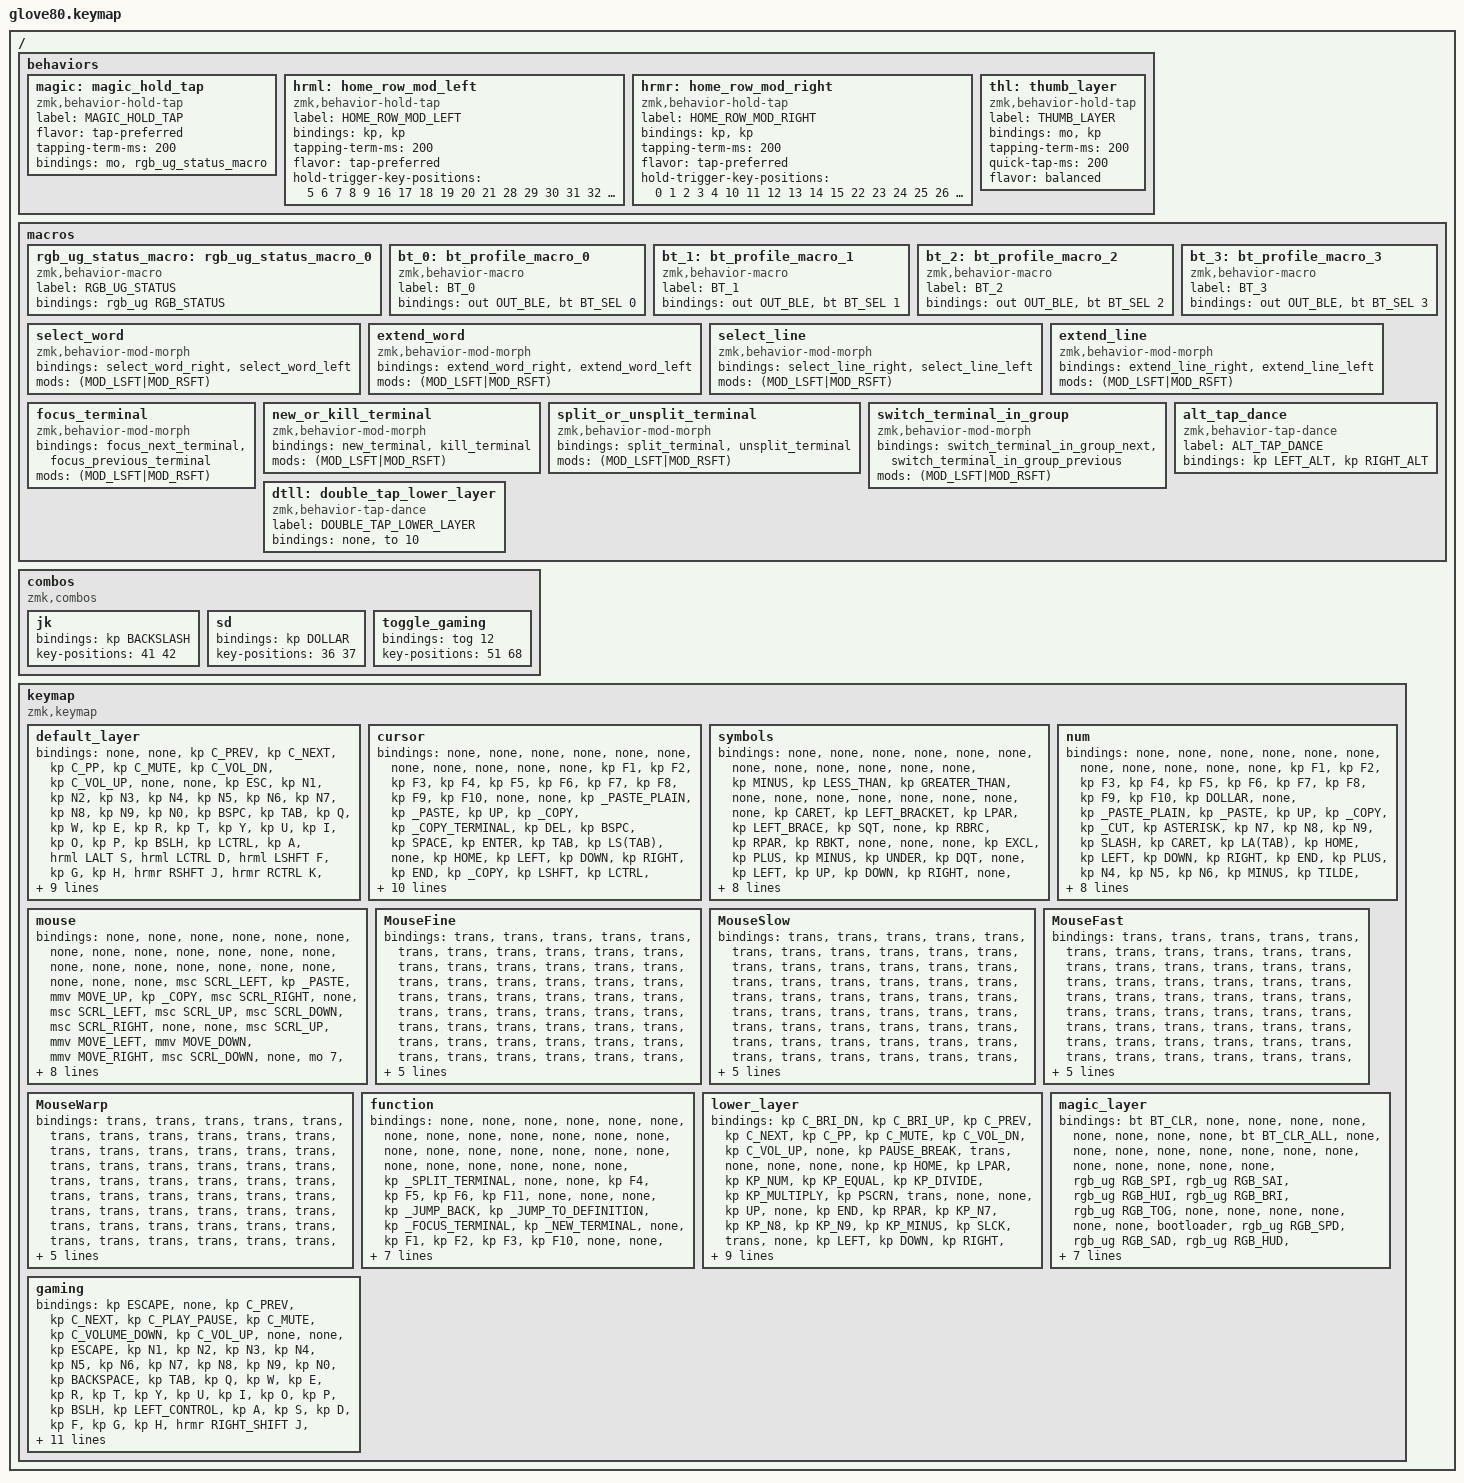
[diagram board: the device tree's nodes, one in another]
#include <input/processors.dtsi>
#include <zephyr/dt-bindings/input/input-event-codes.h>
#include <behaviors.dtsi>
#include <dt-bindings/zmk/bt.h>
#include <dt-bindings/zmk/keys.h>
#include <dt-bindings/zmk/outputs.h>
#include <dt-bindings/zmk/pointing.h>
#include <dt-bindings/zmk/rgb.h>

#define LAYER_MouseFine 5
#define LAYER_MouseSlow 6
#define LAYER_MouseFast 7
#define LAYER_MouseWarp 8

#include "mouse.dtsi"
#include "defs.dtsi"

//------------------------------------------------------------------------
//
// Main
//
//------------------------------------------------------------------------

/ {
    behaviors {
        // For the "layer" key, it'd nice to be able to use it as either a shift or a toggle.
        // Configure it as a tap dance, so the first tap (or hold) is a &mo and the second tap is a &to

        magic: magic_hold_tap {
            compatible = "zmk,behavior-hold-tap";
            label = "MAGIC_HOLD_TAP";
            #binding-cells = <2>;
            flavor = "tap-preferred";
            tapping-term-ms = <200>;
            bindings = <&mo>, <&rgb_ug_status_macro>;
        };

        hrml: home_row_mod_left {
            compatible = "zmk,behavior-hold-tap";
            label = "HOME_ROW_MOD_LEFT";
            bindings = <&kp>, <&kp>;

            #binding-cells = <2>;
            tapping-term-ms = <200>;
            flavor = "tap-preferred";
            hold-trigger-key-positions = <5 6 7 8 9 16 17 18 19 20 21 28 29 30 31 32 33 40 41 42 43 44 45 56 57 58 59 60 61 62 63 72 73 74 75 76 77 78 79 55 38 37 36 35>;
        };

        hrmr: home_row_mod_right {
            compatible = "zmk,behavior-hold-tap";
            label = "HOME_ROW_MOD_RIGHT";
            bindings = <&kp>, <&kp>;

            #binding-cells = <2>;
            tapping-term-ms = <200>;
            flavor = "tap-preferred";
            hold-trigger-key-positions = <0 1 2 3 4 10 11 12 13 14 15 22 23 24 25 26 27 34 35 36 37 38 39 46 47 48 49 50 51 52 53 54 64 65 66 67 68 69 70 71 41 42 43 44>;
        };

        thl: thumb_layer {
            compatible = "zmk,behavior-hold-tap";
            label = "THUMB_LAYER";
            bindings = <&mo>, <&kp>;

            #binding-cells = <2>;
            tapping-term-ms = <200>;
            quick-tap-ms = <200>;
            flavor = "balanced";
        };
    };

    macros {
        //------------------------------------------------------------------------
        //
        // RGB and Bluetooth
        //
        //------------------------------------------------------------------------

        rgb_ug_status_macro: rgb_ug_status_macro_0 {
            label = "RGB_UG_STATUS";
            compatible = "zmk,behavior-macro";
            #binding-cells = <0>;
            bindings = <&rgb_ug RGB_STATUS>;
        };

        bt_0: bt_profile_macro_0 {
            label = "BT_0";
            compatible = "zmk,behavior-macro";
            #binding-cells = <0>;
            bindings = <&out OUT_BLE &bt BT_SEL 0>;
        };

        bt_1: bt_profile_macro_1 {
            label = "BT_1";
            compatible = "zmk,behavior-macro";
            #binding-cells = <0>;
            bindings = <&out OUT_BLE &bt BT_SEL 1>;
        };

        bt_2: bt_profile_macro_2 {
            label = "BT_2";
            compatible = "zmk,behavior-macro";
            #binding-cells = <0>;
            bindings = <&out OUT_BLE &bt BT_SEL 2>;
        };

        bt_3: bt_profile_macro_3 {
            label = "BT_3";
            compatible = "zmk,behavior-macro";
            #binding-cells = <0>;
            bindings = <&out OUT_BLE &bt BT_SEL 3>;
        };

        //------------------------------------------------------------------------
        //
        // Cursor macros
        //
        //------------------------------------------------------------------------
        //
        // SELECT_WORD_DELAY defines how long the macro waits (milliseconds)
        // after moving the cursor before it selects a word.  A larger delay
        // may allow the macro to move to the next word upon each invocation.
        //

        #ifndef SELECT_WORD_DELAY
        #define SELECT_WORD_DELAY 10
        #endif

        #define select_all kp _C(A)

        ZMK_MACRO(

        select_none,
        wait-ms = <SELECT_WORD_DELAY>;
        tap-ms = <SELECT_WORD_DELAY>;
        bindings = <&kp DOWN &kp UP &kp RIGHT &kp LEFT>;

        )

        //
        // select a word (jumps to next word upon each successive invocation)
        //

        select_word: select_word {
            compatible = "zmk,behavior-mod-morph";
            #binding-cells = <0>;
            bindings = <&select_word_right>, <&select_word_left>;

            mods = <(MOD_LSFT|MOD_RSFT)>;
        };

        ZMK_MACRO(

        select_word_right,
        wait-ms = <SELECT_WORD_DELAY>;
        tap-ms = <SELECT_WORD_DELAY>;
        bindings = <&kp _WORD(RIGHT) &kp _WORD(LEFT) &kp _WORD(LS(RIGHT))>;

        )

        ZMK_MACRO(

        select_word_left,
        wait-ms = <SELECT_WORD_DELAY>;
        tap-ms = <SELECT_WORD_DELAY>;
        bindings = <&kp _WORD(LEFT) &kp _WORD(RIGHT) &kp _WORD(LS(LEFT))>;

        )

        //
        // extend current selection by one word
        //

        extend_word: extend_word {
            compatible = "zmk,behavior-mod-morph";
            #binding-cells = <0>;
            bindings = <&extend_word_right>, <&extend_word_left>;

            mods = <(MOD_LSFT|MOD_RSFT)>;
        };

        ZMK_MACRO(

        extend_word_right,
        wait-ms = <SELECT_WORD_DELAY>;
        tap-ms = <SELECT_WORD_DELAY>;
        bindings = <&kp _WORD(LS(RIGHT))>;

        )

        ZMK_MACRO(

        extend_word_left,
        wait-ms = <SELECT_WORD_DELAY>;
        tap-ms = <SELECT_WORD_DELAY>;
        bindings = <&kp _WORD(LS(LEFT))>;

        )

        //
        // select current line
        //

        select_line: select_line {
            compatible = "zmk,behavior-mod-morph";
            #binding-cells = <0>;
            bindings = <&select_line_right>, <&select_line_left>;

            mods = <(MOD_LSFT|MOD_RSFT)>;
        };

        ZMK_MACRO(

        select_line_right,
        wait-ms = <SELECT_WORD_DELAY>;
        tap-ms = <SELECT_WORD_DELAY>;
        bindings = <&kp _HOME &kp _HOME &kp LS(_END)>;

        )

        ZMK_MACRO(

        select_line_left,
        wait-ms = <SELECT_WORD_DELAY>;
        tap-ms = <SELECT_WORD_DELAY>;
        bindings = <&kp _END &kp LS(_HOME)>;

        )

        //
        // extend current selection by one line
        //

        extend_line: extend_line {
            compatible = "zmk,behavior-mod-morph";
            #binding-cells = <0>;
            bindings = <&extend_line_right>, <&extend_line_left>;

            mods = <(MOD_LSFT|MOD_RSFT)>;
        };

        ZMK_MACRO(

        extend_line_right,
        wait-ms = <SELECT_WORD_DELAY>;
        tap-ms = <SELECT_WORD_DELAY>;
        bindings = <&kp LS(DOWN) &kp LS(_END)>;

        )

        ZMK_MACRO(

        extend_line_left,
        wait-ms = <SELECT_WORD_DELAY>;
        tap-ms = <SELECT_WORD_DELAY>;
        bindings = <&kp LS(UP) &kp LS(_HOME)>;

        )

        //------------------------------------------------------------------------
        //
        // VSCode macros
        //
        //------------------------------------------------------------------------

        focus_terminal: focus_terminal {
            compatible = "zmk,behavior-mod-morph";
            #binding-cells = <0>;
            bindings = <&focus_next_terminal>, <&focus_previous_terminal>;

            mods = <(MOD_LSFT|MOD_RSFT)>;
        };

        ZMK_MACRO(

        focus_next_terminal,
        bindings = <&kp _HYPER(F1)>;

        )

        ZMK_MACRO(

        focus_previous_terminal,
        bindings = <&kp _HYPER(F2)>;

        )

        new_or_kill_terminal: new_or_kill_terminal {
            compatible = "zmk,behavior-mod-morph";
            #binding-cells = <0>;
            bindings = <&new_terminal>, <&kill_terminal>;

            mods = <(MOD_LSFT|MOD_RSFT)>;
        };

        ZMK_MACRO(

        new_terminal,
        bindings = <&kp _HYPER(F3)>;

        )

        ZMK_MACRO(

        kill_terminal,
        bindings = <&kp _HYPER(F4)>;

        )

        split_or_unsplit_terminal: split_or_unsplit_terminal {
            compatible = "zmk,behavior-mod-morph";
            #binding-cells = <0>;
            bindings = <&split_terminal>, <&unsplit_terminal>;

            mods = <(MOD_LSFT|MOD_RSFT)>;
        };

        ZMK_MACRO(

        split_terminal,
        bindings = <&kp _HYPER(F5)>;

        )

        ZMK_MACRO(

        unsplit_terminal,
        bindings = <&kp _HYPER(F6)>;

        )

        switch_terminal_in_group: switch_terminal_in_group {
            compatible = "zmk,behavior-mod-morph";
            #binding-cells = <0>;
            bindings =
                <&switch_terminal_in_group_next>,
                <&switch_terminal_in_group_previous>;

            mods = <(MOD_LSFT|MOD_RSFT)>;
        };

        ZMK_MACRO(

        switch_terminal_in_group_next,
        bindings = <&kp LA(DOWN)>;

        )

        ZMK_MACRO(

        switch_terminal_in_group_previous,
        bindings = <&kp LA(UP)>;

        )

        //------------------------------------------------------------------------
        //
        // Other macros
        //
        //------------------------------------------------------------------------

        alt_tap_dance: alt_tap_dance {
            compatible = "zmk,behavior-tap-dance";
            label = "ALT_TAP_DANCE";
            #binding-cells = <0>;
            bindings = <&kp LEFT_ALT>, <&kp RIGHT_ALT>;
        };

        dtll: double_tap_lower_layer {
            compatible = "zmk,behavior-tap-dance";
            label = "DOUBLE_TAP_LOWER_LAYER";
            #binding-cells = <0>;
            bindings = <&none>, <&to 10>;
        };
    };

    combos {
        compatible = "zmk,combos";

        jk {
            bindings = <&kp BACKSLASH>;
            key-positions = <41 42>;
        };

        sd {
            bindings = <&kp DOLLAR>;
            key-positions = <36 37>;
        };

        toggle_gaming {
            bindings = <&tog 12>;
            key-positions = <51 68>;
        };
    };

    keymap {
        compatible = "zmk,keymap";

        default_layer {
            bindings = <
&none      &none     &kp C_PREV    &kp C_NEXT     &kp C_PP                                                                                                     &kp C_MUTE     &kp C_VOL_DN   &kp C_VOL_UP  &none            &none
&kp ESC    &kp N1    &kp N2        &kp N3         &kp N4         &kp N5                                                                                &kp N6  &kp N7         &kp N8         &kp N9        &kp N0           &kp BSPC
&kp TAB    &kp Q     &kp W         &kp E          &kp R          &kp T                                                                                 &kp Y   &kp U          &kp I          &kp O         &kp P            &kp BSLH
&kp LCTRL  &kp A     &hrml LALT S  &hrml LCTRL D  &hrml LSHFT F  &kp G                                                                                 &kp H   &hrmr RSHFT J  &hrmr RCTRL K  &hrmr RALT L  &hrmr RGUI SEMI  &kp ENTER
&kp LSHFT  &kp Z     &kp X         &kp C          &kp V          &kp B   &kp LGUI     &kp LALT    &magic 11 0    &dtll       &caps_word  &kp CAPS      &kp N   &kp M          &kp COMMA      &kp DOT       &kp FSLH         &kp RIGHT_SHIFT
&none      &kp HOME  &kp END       &kp UP         &kp DOWN               &thl 1 BSPC  &thl 3 RET  &thl 9 DELETE  &kp ESCAPE  &thl 4 TAB  &thl 2 SPACE          &kp LEFT       &kp RIGHT      &kp PG_UP     &kp PG_DN        &none
            >;
        };

        cursor {
            bindings = <
&none  &none             &none           &none                    &none                                                                                                                                         &none      &none         &none         &none        &none
&none  &kp F1            &kp F2          &kp F3                   &kp F4     &kp F5                                                                                                                 &kp F6      &kp F7     &kp F8        &kp F9        &kp F10      &none
&none  &kp _PASTE_PLAIN  &kp _PASTE      &kp UP                   &kp _COPY  &kp _COPY_TERMINAL                                                                                                     &kp DEL     &kp BSPC   &kp SPACE     &kp ENTER     &kp TAB      &kp LS(TAB)
&none  &kp HOME          &kp LEFT        &kp DOWN                 &kp RIGHT  &kp END                                                                                                                &kp _COPY   &kp LSHFT  &kp LCTRL     &kp LALT      &kp LGUI     &none
&none  &kp PG_UP         &kp _JUMP_BACK  &kp _JUMP_TO_DEFINITION  &kp _CUT   &kp PG_DN           &none  &none  &none  &none                      &none                       &new_or_kill_terminal  &kp _PASTE  &kp _FIND  &select_word  &select_line  &select_all  &select_none
&none  &none             &kp LBKT        &kp LBRC                 &kp LPAR                       &none  &none  &none  &switch_terminal_in_group  &split_or_unsplit_terminal  &focus_terminal                    &none      &extend_word  &extend_line  &none        &none
            >;
        };

        //         navnum {
        //             bindings = <
        // &none        &none             &none       &none      &none                                                                                                     &none      &none      &none     &none        &none
        // &none        &kp F1            &kp F2      &kp F3     &kp F4         &kp F5                                                                       &kp F6        &kp F7     &kp F8     &kp F9    &kp F10      &kp DOLLAR
        // &none        &kp _PASTE_PLAIN  &kp _PASTE  &kp UP     &kp _COPY      &kp _CUT                                                                     &kp ASTERISK  &kp N4     &kp N5     &kp N6    &kp SLASH    &kp CARET
        // &kp LA(TAB)  &kp HOME          &kp LEFT    &kp DOWN   &kp RIGHT      &kp END                                                                      &kp PLUS      &kp N1     &kp N2     &kp N3    &kp MINUS    &kp TILDE
        // &kp LS(TAB)  &kp TAB           &kp ENTER   &kp SPACE  &kp BACKSPACE  &kp DELETE  &none  &none  &none  &kp LESS_THAN  &kp GREATER_THAN  &kp EQUAL  &kp COLON     &kp N7     &kp N8     &kp N9    &kp PERCENT  &kp UNDERSCORE
        // &none        &none             &kp LBKT    &kp LBRC   &kp LPAR                   &none  &none  &none  &kp COMMA      &kp PERIOD        &kp N0                   &kp LSHFT  &kp LCTRL  &kp LALT  &none        &none
        //             >;
        //         };

        symbols {
            bindings = <
&none  &none        &none             &none          &none                                                                                              &none           &none             &none         &none      &none
&none  &none        &kp MINUS         &kp LESS_THAN  &kp GREATER_THAN  &none                                                                &none       &none           &none             &none         &none      &none
&none  &kp CARET    &kp LEFT_BRACKET  &kp LPAR       &kp LEFT_BRACE    &kp SQT                                                              &none       &kp RBRC        &kp RPAR          &kp RBKT      &none      &none
&none  &kp EXCL     &kp PLUS          &kp MINUS      &kp UNDER         &kp DQT                                                              &none       &kp LEFT        &kp UP            &kp DOWN      &kp RIGHT  &none
&none  &kp PERCENT  &kp ASTERISK      &kp SLASH      &kp COLON         &kp GRAVE  &kp DOLLAR  &kp PIPE  &kp AMPERSAND  &none  &none  &none  &kp DELETE  &kp BACKSPACE   &kp SPACE         &kp ENTER     &kp TAB    &kp LS(TAB)
&none  &none        &none             &kp TILDE      &kp PIPE                     &kp EQUAL   &kp HASH  &kp AT         &none  &none  &none              &kp LEFT_SHIFT  &kp LEFT_CONTROL  &kp LEFT_ALT  &none      &none
            >;
        };

        num {
            bindings = <
&none        &none             &none       &none      &none                                                                                                     &none      &none      &none     &none        &none
&none        &kp F1            &kp F2      &kp F3     &kp F4         &kp F5                                                                       &kp F6        &kp F7     &kp F8     &kp F9    &kp F10      &kp DOLLAR
&none        &kp _PASTE_PLAIN  &kp _PASTE  &kp UP     &kp _COPY      &kp _CUT                                                                     &kp ASTERISK  &kp N7     &kp N8     &kp N9    &kp SLASH    &kp CARET
&kp LA(TAB)  &kp HOME          &kp LEFT    &kp DOWN   &kp RIGHT      &kp END                                                                      &kp PLUS      &kp N4     &kp N5     &kp N6    &kp MINUS    &kp TILDE
&kp LS(TAB)  &kp TAB           &kp ENTER   &kp SPACE  &kp BACKSPACE  &kp DELETE  &none  &none  &none  &kp LESS_THAN  &kp GREATER_THAN  &kp EQUAL  &kp COLON     &kp N1     &kp N2     &kp N3    &kp PERCENT  &kp UNDERSCORE
&none        &none             &kp GRAVE   &kp DQT    &kp SQT                    &none  &none  &none  &kp COMMA      &kp PERIOD        &kp N0                   &kp LSHFT  &kp LCTRL  &kp LALT  &none        &none
            >;
        };

        //         cursor {
        //             bindings = <
        // &none        &none      &none       &none              &none                                                                                             &none           &none             &none           &none         &none
        // &none        &none      &none       &none              &none             &none                                                               &none       &none           &none             &none           &none         &none
        // &none        &kp PG_UP  &kp _PASTE  &kp UP             &kp _COPY         &kp PG_DN                                                           &kp _CUT    &kp _FIND       &kp _FIND_NEXT    &kp _FIND_PREV  &kp _REPLACE  &none
        // &none        &kp HOME   &kp LEFT    &kp DOWN           &kp RIGHT         &kp END                                                             &kp _COPY   &kp LEFT_SHIFT  &kp LEFT_CONTROL  &kp LEFT_ALT    &kp LEFT_WIN  &none
        // &kp LS(TAB)  &kp TAB    &kp ENTER   &kp SPACE          &kp BACKSPACE     &kp DELETE  &none  &none  &none  &none  &none  &none                &kp _PASTE  &none           &select_word      &select_line    &select_all   &select_none
        // &none        &none      &kp GRAVE   &kp DOUBLE_QUOTES  &kp SINGLE_QUOTE              &none  &none  &none  &none  &none  &kp _FOCUS_TERMINAL              &none           &extend_word      &extend_line    &none         &none
        //             >;
        //         };

        mouse {
            bindings = <
&none  &none           &none           &none           &none                                                                                                  &none           &none         &none           &none            &none
&none  &none           &none           &none           &none            &none                                                                          &none  &none           &none         &none           &none            &none
&none  &msc SCRL_LEFT  &kp _PASTE      &mmv MOVE_UP    &kp _COPY        &msc SCRL_RIGHT                                                                &none  &msc SCRL_LEFT  &msc SCRL_UP  &msc SCRL_DOWN  &msc SCRL_RIGHT  &none
&none  &msc SCRL_UP    &mmv MOVE_LEFT  &mmv MOVE_DOWN  &mmv MOVE_RIGHT  &msc SCRL_DOWN                                                                 &none  &mo 7           &mo 6         &mo 8           &mo 5            &none
&none  &none           &none           &none           &none            &none            &mkp MCLK  &kp K_CONTEXT_MENU  &mkp MB5  &none  &none  &none  &none  &mmv MOVE_LEFT  &mmv MOVE_UP  &mmv MOVE_DOWN  &mmv MOVE_RIGHT  &none
&none  &none           &none           &none           &none                             &mkp LCLK  &mkp RCLK           &mkp MB4  &none  &none  &none         &none           &mkp LCLK     &mkp RCLK       &none            &none
            >;
        };

        MouseFine {
            bindings = <
&trans  &trans  &trans  &trans  &trans                                                                  &trans  &trans  &trans  &trans  &trans
&trans  &trans  &trans  &trans  &trans  &trans                                                  &trans  &trans  &trans  &trans  &trans  &trans
&trans  &trans  &trans  &trans  &trans  &trans                                                  &trans  &trans  &trans  &trans  &trans  &trans
&trans  &trans  &trans  &trans  &trans  &trans                                                  &trans  &trans  &trans  &trans  &trans  &trans
&trans  &trans  &trans  &trans  &trans  &trans  &trans  &trans  &trans  &trans  &trans  &trans  &trans  &trans  &trans  &trans  &trans  &trans
&trans  &trans  &trans  &trans  &trans          &trans  &trans  &trans  &trans  &trans  &trans          &trans  &trans  &trans  &trans  &trans
            >;
        };

        MouseSlow {
            bindings = <
&trans  &trans  &trans  &trans  &trans                                                                  &trans  &trans  &trans  &trans  &trans
&trans  &trans  &trans  &trans  &trans  &trans                                                  &trans  &trans  &trans  &trans  &trans  &trans
&trans  &trans  &trans  &trans  &trans  &trans                                                  &trans  &trans  &trans  &trans  &trans  &trans
&trans  &trans  &trans  &trans  &trans  &trans                                                  &trans  &trans  &trans  &trans  &trans  &trans
&trans  &trans  &trans  &trans  &trans  &trans  &trans  &trans  &trans  &trans  &trans  &trans  &trans  &trans  &trans  &trans  &trans  &trans
&trans  &trans  &trans  &trans  &trans          &trans  &trans  &trans  &trans  &trans  &trans          &trans  &trans  &trans  &trans  &trans
            >;
        };

        MouseFast {
            bindings = <
&trans  &trans  &trans  &trans  &trans                                                                  &trans  &trans  &trans  &trans  &trans
&trans  &trans  &trans  &trans  &trans  &trans                                                  &trans  &trans  &trans  &trans  &trans  &trans
&trans  &trans  &trans  &trans  &trans  &trans                                                  &trans  &trans  &trans  &trans  &trans  &trans
&trans  &trans  &trans  &trans  &trans  &trans                                                  &trans  &trans  &trans  &trans  &trans  &trans
&trans  &trans  &trans  &trans  &trans  &trans  &trans  &trans  &trans  &trans  &trans  &trans  &trans  &trans  &trans  &trans  &trans  &trans
&trans  &trans  &trans  &trans  &trans          &trans  &trans  &trans  &trans  &trans  &trans          &trans  &trans  &trans  &trans  &trans
            >;
        };

        MouseWarp {
            bindings = <
&trans  &trans  &trans  &trans  &trans                                                                  &trans  &trans  &trans  &trans  &trans
&trans  &trans  &trans  &trans  &trans  &trans                                                  &trans  &trans  &trans  &trans  &trans  &trans
&trans  &trans  &trans  &trans  &trans  &trans                                                  &trans  &trans  &trans  &trans  &trans  &trans
&trans  &trans  &trans  &trans  &trans  &trans                                                  &trans  &trans  &trans  &trans  &trans  &trans
&trans  &trans  &trans  &trans  &trans  &trans  &trans  &trans  &trans  &trans  &trans  &trans  &trans  &trans  &trans  &trans  &trans  &trans
&trans  &trans  &trans  &trans  &trans          &trans  &trans  &trans  &trans  &trans  &trans          &trans  &trans  &trans  &trans  &trans
            >;
        };

        function {
            bindings = <
&none  &none  &none           &none                    &none                                                                                                                  &none   &none   &none   &none    &none
&none  &none  &none           &none                    &none                     &none                                                                                 &none  &none   &none   &none   &none    &none
&none  &none  &none           &none                    &kp _SPLIT_TERMINAL       &none                                                                                 &none  &kp F4  &kp F5  &kp F6  &kp F11  &none
&none  &none  &kp _JUMP_BACK  &kp _JUMP_TO_DEFINITION  &kp _FOCUS_TERMINAL       &kp _NEW_TERMINAL                                                                     &none  &kp F1  &kp F2  &kp F3  &kp F10  &none
&none  &none  &none           &none                    &kp _NEW_TERMINAL_WINDOW  &none              &none  &none  &none  &none           &none       &kp C_MUTE        &none  &kp F7  &kp F8  &kp F9  &kp F12  &none
&none  &none  &none           &none                    &none                                        &none  &none  &none  &kp C_PREVIOUS  &kp C_NEXT  &kp C_PLAY_PAUSE         &none   &none   &none   &none    &none
            >;
        };

        lower_layer {
            bindings = <
&kp C_BRI_DN  &kp C_BRI_UP  &kp C_PREV  &kp C_NEXT  &kp C_PP                                                                         &kp C_MUTE  &kp C_VOL_DN  &kp C_VOL_UP   &none            &kp PAUSE_BREAK
&trans        &none         &none       &none       &none      &kp HOME                                                   &kp LPAR   &kp KP_NUM  &kp KP_EQUAL  &kp KP_DIVIDE  &kp KP_MULTIPLY  &kp PSCRN
&trans        &none         &none       &kp UP      &none      &kp END                                                    &kp RPAR   &kp KP_N7   &kp KP_N8     &kp KP_N9      &kp KP_MINUS     &kp SLCK
&trans        &none         &kp LEFT    &kp DOWN    &kp RIGHT  &kp PG_UP                                                  &kp PRCNT  &kp KP_N4   &kp KP_N5     &kp KP_N6      &kp KP_PLUS      &none
&trans        &kp K_CMENU   &none       &kp F11     &kp F12    &kp PG_DN  &trans  &trans  &to 0   &trans  &trans  &trans  &kp COMMA  &kp KP_N1   &kp KP_N2     &kp KP_N3      &kp KP_ENTER     &trans
&trans        &kp CAPS      &kp INS     &kp F11     &kp F12               &trans  &trans  &trans  &trans  &trans  &trans             &kp KP_N0   &kp KP_N0     &kp KP_DOT     &kp KP_ENTER     &trans
            >;
        };

        magic_layer {
            bindings = <
&bt BT_CLR   &none            &none            &none            &none                                                                                     &none  &none  &none  &none  &bt BT_CLR_ALL
&none        &none            &none            &none            &none            &none                                                             &none  &none  &none  &none  &none  &none
&none        &rgb_ug RGB_SPI  &rgb_ug RGB_SAI  &rgb_ug RGB_HUI  &rgb_ug RGB_BRI  &rgb_ug RGB_TOG                                                   &none  &none  &none  &none  &none  &none
&bootloader  &rgb_ug RGB_SPD  &rgb_ug RGB_SAD  &rgb_ug RGB_HUD  &rgb_ug RGB_BRD  &rgb_ug RGB_EFF                                                   &none  &none  &none  &none  &none  &bootloader
&sys_reset   &none            &none            &none            &none            &none            &bt_2  &bt_3  &none         &none  &none  &none  &none  &none  &none  &none  &none  &sys_reset
&none        &none            &none            &none            &none                             &bt_0  &bt_1  &out OUT_USB  &none  &none  &none         &none  &none  &none  &none  &to 0
            >;
        };

        gaming {
            bindings = <
&kp ESCAPE        &none     &kp C_PREV  &kp C_NEXT    &kp C_PLAY_PAUSE                                                                                                   &kp C_MUTE           &kp C_VOLUME_DOWN     &kp C_VOL_UP       &none                 &none
&kp ESCAPE        &kp N1    &kp N2      &kp N3        &kp N4            &kp N5                                                                                   &kp N6  &kp N7               &kp N8                &kp N9             &kp N0                &kp BACKSPACE
&kp TAB           &kp Q     &kp W       &kp E         &kp R             &kp T                                                                                    &kp Y   &kp U                &kp I                 &kp O              &kp P                 &kp BSLH
&kp LEFT_CONTROL  &kp A     &kp S       &kp D         &kp F             &kp G                                                                                    &kp H   &hrmr RIGHT_SHIFT J  &hrmr LEFT_CONTROL K  &hrmr RIGHT_ALT L  &hrmr RIGHT_WIN SEMI  &kp ENTER
&kp LEFT_SHIFT    &kp Z     &kp X       &kp C         &kp V             &kp B   &kp LEFT_GUI  &kp LALT          &none      &dtll       &caps_word  &kp CAPSLOCK  &kp N   &kp M                &kp COMMA             &kp DOT            &kp FSLH              &kp RIGHT_SHIFT
&kp LEFT_CONTROL  &kp HOME  &kp END     &kp UP_ARROW  &kp DOWN_ARROW            &kp SPACE     &kp LEFT_CONTROL  &kp ENTER  &kp ESCAPE  &thl 4 TAB  &thl 2 SPACE          &kp LEFT_ARROW       &kp RIGHT_ARROW       &kp PG_UP          &kp PG_DN             &none
            >;
        };
    };
};
